# STM32L4R5 register map
File version: 2.4
CPU: CM4 r0p1, little endian, MPU, FPU, 4 interrupt priority bits
Registers are 32-bit, read-write, reset 0x0 unless marked. A register's access mark holds for its fields unless they carry their own. Offsets are from the block's base; [hi:lo] are bit positions; lines under a group give offsets from that group; {n}, {i} and the like mark numbered series; 'fields as' and 'values as' point back to an identical list.

## DMA1 — Direct memory access controller
Base 0x40020000
Same registers: DMA2 0x40020400
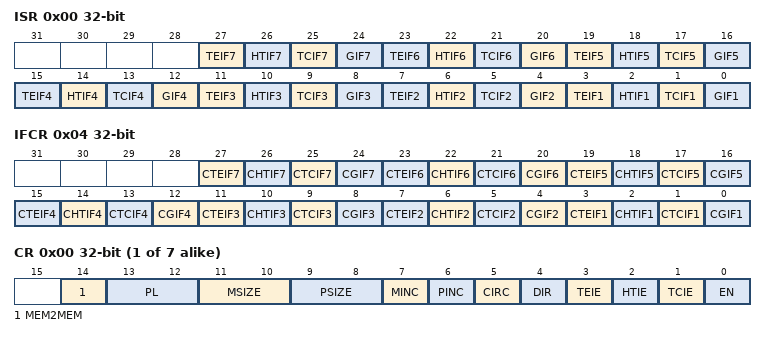
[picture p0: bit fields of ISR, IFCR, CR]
0x00 ISR ro — interrupt status register
  [4n-1] TEIF{n} (n=1..7) — Channel {n} Transfer Error flag
    0=NoError (No transfer error); 1=Error (A transfer error has occured)
  [4n-2] HTIF{n} (n=1..7) — Channel {n} Half Transfer Complete flag
    0=NotHalf (No half transfer event); 1=Half (A half transfer event has occured)
  [4n-3] TCIF{n} (n=1..7) — Channel {n} Transfer Complete flag
    0=NotComplete (No transfer complete event); 1=Complete (A transfer complete event has occured)
  [4n-4] GIF{n} (n=1..7) — Channel {n} Global interrupt flag
    0=NoEvent (No transfer error, half event, complete event); 1=Event (A transfer error, half event or complete event has occured)
0x04 IFCR wo — interrupt flag clear register
  [4n-1] CTEIF{n} (n=1..7) — Channel {n} Transfer Error clear
    1=Clears the TEIF flag in the ISR register
  [4n-2] CHTIF{n} (n=1..7) — Channel {n} Half Transfer clear
    1=Clears the HTIF flag in the ISR register
  [4n-3] CTCIF{n} (n=1..7) — Channel {n} Transfer Complete clear
    1=Clears the TCIF flag in the ISR register
  [4n-4] CGIF{n} (n=1..7) — Channel {n} Global interrupt clear
    1=Clears the GIF, TEIF, HTIF, TCIF flags in the ISR register
0x08 CH{i} (i=1..7; step 0x14) group — Channel cluster: CCR?, CNDTR?, CPAR?, and CMAR? registers
  0x00 CR — channel x configuration register
    [14] MEM2MEM — Memory to memory mode
      0=Disabled (Memory to memory mode disabled); 1=Enabled (Memory to memory mode enabled)
    [13:12] PL — Channel priority level
      0=Low (Low priority); 1=Medium priority; 2=High priority; 3=Very high priority
    [11:10] MSIZE — Memory size
      0=Bits8 (8-bit size); 1=Bits16 (16-bit size); 2=Bits32 (32-bit size)
    [9:8] PSIZE — Peripheral size
      values as MSIZE
    [7] MINC — Memory increment mode
      0=Disabled (Increment mode disabled); 1=Enabled (Increment mode enabled)
    [6] PINC — Peripheral increment mode
      values as MINC
    [5] CIRC — Circular mode
      0=Disabled (Circular buffer disabled); 1=Enabled (Circular buffer enabled)
    [4] DIR — Data transfer direction
      0=FromPeripheral (Read from peripheral); 1=FromMemory (Read from memory)
    [3] TEIE — Transfer error interrupt enable
      0=Disabled (Transfer Error interrupt disabled); 1=Enabled (Transfer Error interrupt enabled)
    [2] HTIE — Half transfer interrupt enable
      0=Disabled (Half Transfer interrupt disabled); 1=Enabled (Half Transfer interrupt enabled)
    [1] TCIE — Transfer complete interrupt enable
      0=Disabled (Transfer Complete interrupt disabled); 1=Enabled (Transfer Complete interrupt enabled)
    [0] EN — Channel enable
      0=Disabled (Channel disabled); 1=Enabled (Channel enabled)
  0x04 NDTR — channel x number of data register
    [15:0] NDT — Number of data to transfer
  0x08 PAR — channel x peripheral address register
    [31:0] PA — Peripheral address
  0x0C MAR — channel x memory address register
    [31:0] MA — Memory address

## DMAMUX1 — DMA request multiplexer
Base 0x40020800
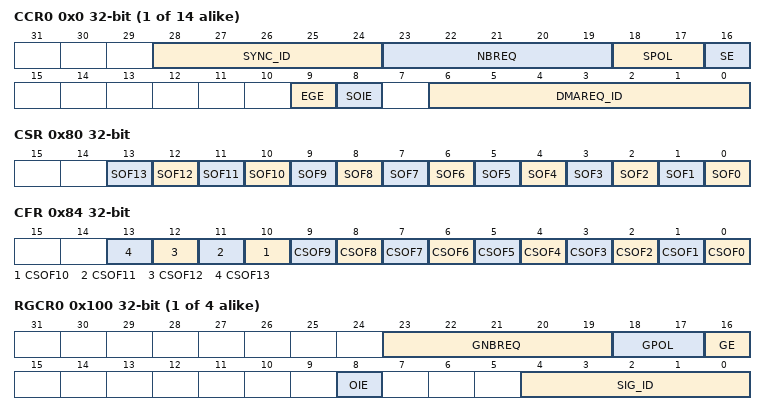
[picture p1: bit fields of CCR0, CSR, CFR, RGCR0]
{0x0+4i} CCR{i} (i=0..13) — DMA Multiplexer Channel {i} Control register
  [28:24] SYNC_ID — Synchronization identification
  [23:19] NBREQ — Number of DMA requests minus 1 to forward
  [18:17] SPOL — Synchronization polarity
    0=NoEdge (No event, i.e. no synchronization nor detection); 1=RisingEdge; 2=FallingEdge; 3=BothEdges (Rising and falling edges)
  [16] SE — Synchronization enable
    0=Disabled (Synchronization disabled); 1=Enabled (Synchronization enabled)
  [9] EGE — Event generation enable
    0=Disabled (Event generation disabled); 1=Enabled (Event generation enabled)
  [8] SOIE — Synchronization overrun interrupt enable
    0=Disabled (Synchronization overrun interrupt disabled); 1=Enabled (Synchronization overrun interrupt enabled)
  [6:0] DMAREQ_ID — DMA request identification
0x80 CSR ro — channel status register
  [n] SOF{n} (n=0..13) — Synchronization Overrun Flag {n}
    0=NoSyncEvent (No synchronization event occured on a DMA request line multiplexer channel x, while the DMA request counter value is lower than NBREQ); 1=SyncEvent (Synchronization event occured on a DMA request line multiplexer channel x, while the DMA request counter value is lower than NBREQ)
0x84 CFR wo — clear flag register
  [n] CSOF{n} (n=0..13) write-1-clears — Synchronization Clear Overrun Flag {n}
    1=Clear synchronization flag
{0x100+4i} RGCR{i} (i=0..3) — request generator channel {i} configuration register
  [23:19] GNBREQ — Number of DMA requests to be generated minus 1
  [18:17] GPOL — DMA request generator trigger polarity
    0=NoEdge (No event, i.e. no detection nor generation); 1=RisingEdge; 2=FallingEdge; 3=BothEdges (Rising and falling edges)
  [16] GE — DMA request generator channel 0 enable
    0=Disabled (DMA request generation disabled); 1=Enabled (DMA request enabled)
  [8] OIE — Trigger overrun interrupt enable
    0=Disabled (Trigger overrun interrupt disabled); 1=Enabled (Trigger overrun interrupt enabled)
  [4:0] SIG_ID — Signal identification
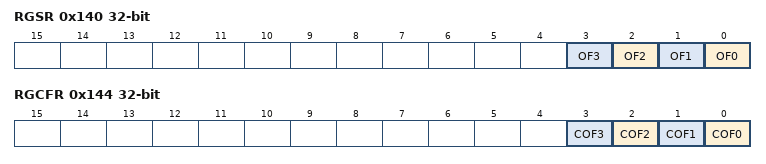
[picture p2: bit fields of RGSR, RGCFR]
0x140 RGSR ro — request generator interrupt status register
  [n] OF{n} (n=0..3) — Generator Overrun Flag {n}
    0=NoTrigger (No new trigger event occured on DMA request generator channel x, before the request counter underrun); 1=Trigger (New trigger event occured on DMA request generator channel x, before the request counter underrun)
0x144 RGCFR wo — request generator interrupt clear flag register
  [n] COF{n} (n=0..3) write-1-clears — Generator Clear Overrun Flag {n}
    1=Clear overrun flag
